# COMPUTE_CLUSTER0_CTL_CFG_PHY register map
Vendor: Texas Instruments
Registers are 32-bit, read-write, reset 0x0 unless marked. A register's access mark holds for its fields unless they carry their own. Offsets are as the file gives them; [hi:lo] are bit positions; {n}, {i} and the like mark numbered series.

## COMPUTE_CLUSTER0_CTL_CFG_PHY (part 4 of 4)
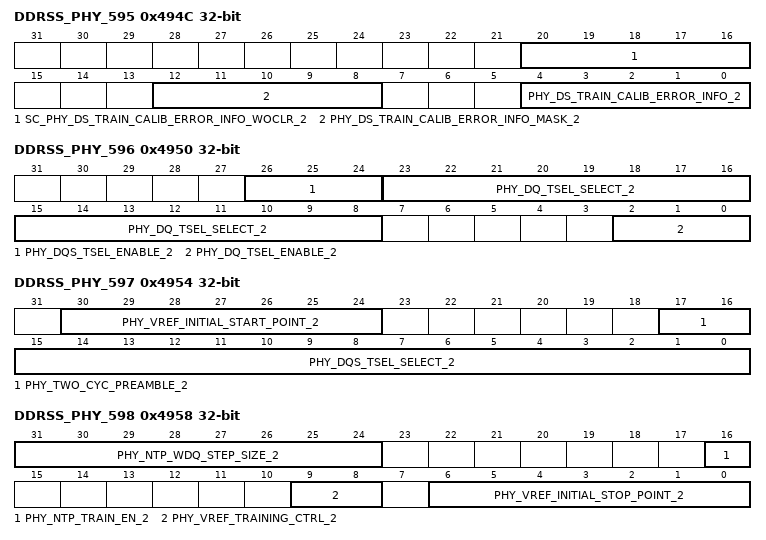
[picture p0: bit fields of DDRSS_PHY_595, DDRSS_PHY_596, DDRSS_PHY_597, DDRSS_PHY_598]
0x494C DDRSS_PHY_595 access per field
  [20:16] SC_PHY_DS_TRAIN_CALIB_ERROR_INFO_WOCLR_2 wo — Data slice level training/calibration Error Info for slice 2.
  [12:8] PHY_DS_TRAIN_CALIB_ERROR_INFO_MASK_2 rw — Data slice level training/calibration Error Info Mask for slice 2.
  [4:0] PHY_DS_TRAIN_CALIB_ERROR_INFO_2 ro — Data slice level training/calibration Error Info for slice 2.
0x4950 DDRSS_PHY_596
  [26:24] PHY_DQS_TSEL_ENABLE_2 — Operation type tsel enables for DQS signals for slice 2.
  [23:8] PHY_DQ_TSEL_SELECT_2 — Operation type tsel select values for DQ/DM signals for slice 2.
  [2:0] PHY_DQ_TSEL_ENABLE_2 — Operation type tsel enables for DQ/DM signals for slice 2.
0x4954 DDRSS_PHY_597
  [30:24] PHY_VREF_INITIAL_START_POINT_2 — Data slice initial VREF training start value for slice 2.
  [17:16] PHY_TWO_CYC_PREAMBLE_2 — 2 cycle preamble support for slice 2.
  [15:0] PHY_DQS_TSEL_SELECT_2 — Operation type tsel select values for DQS signals for slice 2.
0x4958 DDRSS_PHY_598
  [31:24] PHY_NTP_WDQ_STEP_SIZE_2 — Step size of WR DQ slave delay during No-Topology training for slice 2.
  [16] PHY_NTP_TRAIN_EN_2 — Enable for No-Topology training for slice 2.
  [9:8] PHY_VREF_TRAINING_CTRL_2 — Data slice vref training enable control for slice 2.
  [6:0] PHY_VREF_INITIAL_STOP_POINT_2 — Data slice initial VREF training stop value for slice 2.
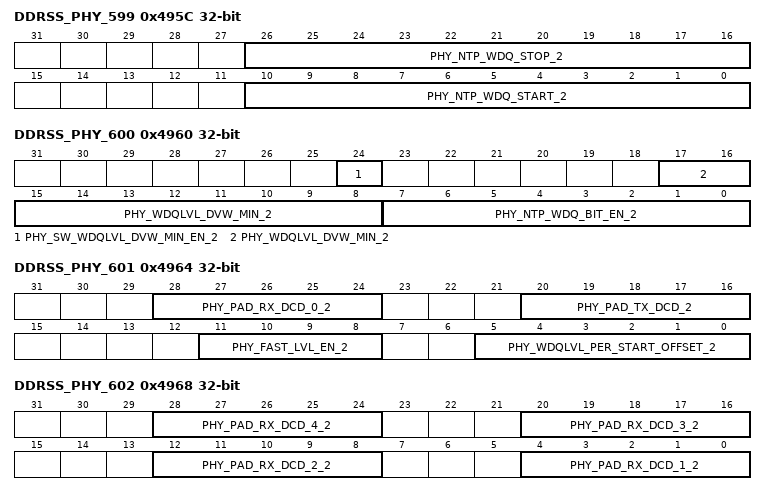
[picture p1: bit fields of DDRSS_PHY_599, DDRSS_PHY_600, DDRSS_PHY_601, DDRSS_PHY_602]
0x495C DDRSS_PHY_599
  [26:16] PHY_NTP_WDQ_STOP_2 — End of WR DQ slave delay in No-Topology training for slice 2.
  [10:0] PHY_NTP_WDQ_START_2 — Starting WR DQ slave delay in No-Topology training for slice 2.
0x4960 DDRSS_PHY_600
  [24] PHY_SW_WDQLVL_DVW_MIN_EN_2 — SW override to enable use of PHY_WDQLVL_DVW_MIN for slice 2.
  [17:8] PHY_WDQLVL_DVW_MIN_2 — Minimum data valid window across DQs and ranks for slice 2.
  [7:0] PHY_NTP_WDQ_BIT_EN_2 — Enable Bit for WR DQ during No-Topology training for slice 2.
0x4964 DDRSS_PHY_601
  [28:24] PHY_PAD_RX_DCD_0_2 — Controls RX_DCD pin for each pad for slice 2.
  [20:16] PHY_PAD_TX_DCD_2 — Controls TX_DCD pin for each pad for slice 2.
  [11:8] PHY_FAST_LVL_EN_2 — Enable for fast multi-pattern window search for slice 2.
  [5:0] PHY_WDQLVL_PER_START_OFFSET_2 — Peridic training start point offset for slice 2.
0x4968 DDRSS_PHY_602
  [8n-4:8n-8] PHY_PAD_RX_DCD_{n}_2 (n=1..4) — Controls RX_DCD pin for each pad for slice 2.
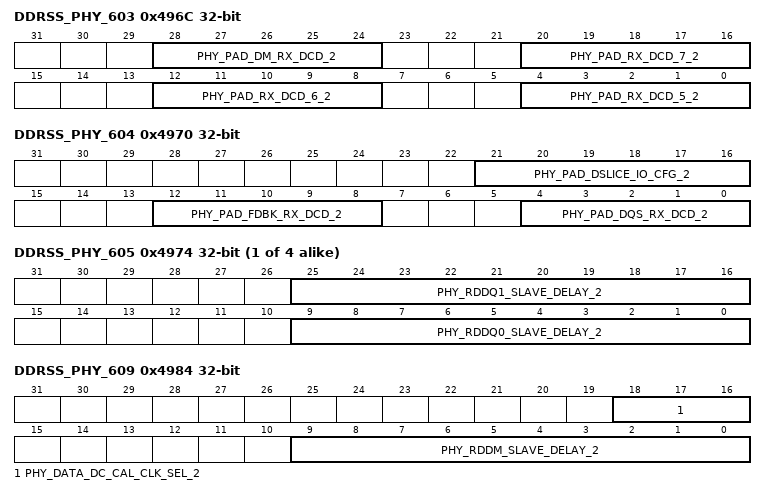
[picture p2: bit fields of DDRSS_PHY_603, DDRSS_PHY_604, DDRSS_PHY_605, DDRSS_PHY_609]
0x496C DDRSS_PHY_603
  [28:24] PHY_PAD_DM_RX_DCD_2 — Controls RX_DCD pin for dm pad for slice 2.
  [20:16] PHY_PAD_RX_DCD_7_2 — Controls RX_DCD pin for each pad for slice 2.
  [12:8] PHY_PAD_RX_DCD_6_2 — Controls RX_DCD pin for each pad for slice 2.
  [4:0] PHY_PAD_RX_DCD_5_2 — Controls RX_DCD pin for each pad for slice 2.
0x4970 DDRSS_PHY_604
  [21:16] PHY_PAD_DSLICE_IO_CFG_2 — Controls PCLK/PARK pin for pad for slice 2.
  [12:8] PHY_PAD_FDBK_RX_DCD_2 — Controls RX_DCD pin for fdbk pad for slice 2.
  [4:0] PHY_PAD_DQS_RX_DCD_2 — Controls RX_DCD pin for dqs pad for slice 2.
{0x4000+4i} DDRSS_PHY_{i} (i=605..608)
  [25:16] PHY_RDDQ{2i-1209}_SLAVE_DELAY_2 — Read DQ{2i-1209} slave delay setting for slice 2.
  [9:0] PHY_RDDQ{2i-1210}_SLAVE_DELAY_2 — Read DQ{2i-1210} slave delay setting for slice 2.
0x4984 DDRSS_PHY_609
  [18:16] PHY_DATA_DC_CAL_CLK_SEL_2 — Determines DCC CAL clock for slice 2.
  [9:0] PHY_RDDM_SLAVE_DELAY_2 — Read DM/DBI slave delay setting for slice 2.
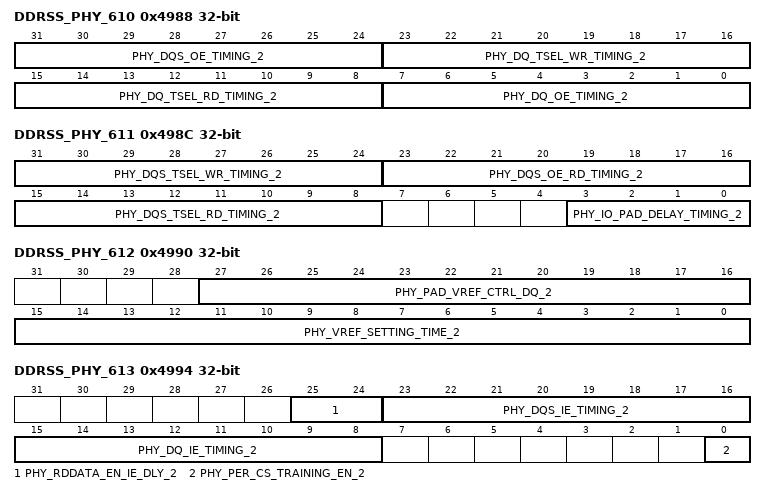
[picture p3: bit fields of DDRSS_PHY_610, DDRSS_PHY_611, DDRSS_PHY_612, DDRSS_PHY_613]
0x4988 DDRSS_PHY_610
  [31:24] PHY_DQS_OE_TIMING_2 — Start/end timing values for DQS output enable signals for slice 2.
  [23:16] PHY_DQ_TSEL_WR_TIMING_2 — Start/end timing values for DQ/DM write based termination enable and select signals for slice 2.
  [15:8] PHY_DQ_TSEL_RD_TIMING_2 — Start/end timing values for DQ/DM read based termination enable and select signals for slice 2.
  [7:0] PHY_DQ_OE_TIMING_2 — Start/end timing values for DQ/DM output enable signals for slice 2.
0x498C DDRSS_PHY_611
  [31:24] PHY_DQS_TSEL_WR_TIMING_2 — Start/end timing values for DQS write based termination enable and select signals for slice 2.
  [23:16] PHY_DQS_OE_RD_TIMING_2 — Start/end timing values for DQS read based OE extension for slice 2.
  [15:8] PHY_DQS_TSEL_RD_TIMING_2 — Start/end timing values for DQS read based termination enable and select signals for slice 2.
  [3:0] PHY_IO_PAD_DELAY_TIMING_2 — Feedback pad's OPAD and IPAD delay timing for slice 2.
0x4990 DDRSS_PHY_612
  [27:16] PHY_PAD_VREF_CTRL_DQ_2 — Pad VREF control settings for DQ slice 2.
  [15:0] PHY_VREF_SETTING_TIME_2 — Number of cycles for vref settle after setting is changed for slice 2.
0x4994 DDRSS_PHY_613
  [25:24] PHY_RDDATA_EN_IE_DLY_2 — Number of cycles that the dfi_rddata_en signal is earlier than necessary for input enable generation for slice 2.
  [23:16] PHY_DQS_IE_TIMING_2 — Start/end timing values for DQS input enable signals for slice 2.
  [15:8] PHY_DQ_IE_TIMING_2 — Start/end timing values for DQ/DM input enable signals for slice 2.
  [0] PHY_PER_CS_TRAINING_EN_2 — Enables the per-rank training and read/write timing capabilities for slice 2.
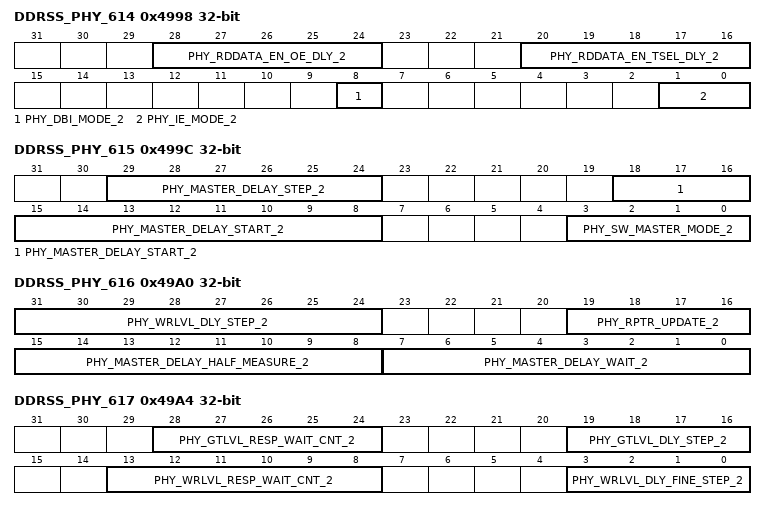
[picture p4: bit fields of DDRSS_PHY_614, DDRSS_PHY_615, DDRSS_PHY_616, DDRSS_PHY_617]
0x4998 DDRSS_PHY_614
  [28:24] PHY_RDDATA_EN_OE_DLY_2 — Number of cycles that the dfi_rddata_en signal is earlier than necessary for LP4 OE extension generation for slice 2.
  [20:16] PHY_RDDATA_EN_TSEL_DLY_2 — Number of cycles that the dfi_rddata_en signal is earlier than necessary for TSEL enable generation for slice 2.
  [8] PHY_DBI_MODE_2 — DBI mode for slice 2.
  [1:0] PHY_IE_MODE_2 — Input enable mode bits for slice 2.
0x499C DDRSS_PHY_615
  [29:24] PHY_MASTER_DELAY_STEP_2 — Incremental step size for master delay line locking algorithm for slice 2.
  [18:8] PHY_MASTER_DELAY_START_2 — Start value for master delay line locking algorithm for slice 2.
  [3:0] PHY_SW_MASTER_MODE_2 — Master delay line override settings for slice 2.
0x49A0 DDRSS_PHY_616
  [31:24] PHY_WRLVL_DLY_STEP_2 — DQS slave delay step size during write leveling for slice 2.
  [19:16] PHY_RPTR_UPDATE_2 — Offset in cycles from the dfi_rddata_en signal to release data from the entry FIFO for slice 2.
  [15:8] PHY_MASTER_DELAY_HALF_MEASURE_2 — Defines the number of delay line elements to be considered in determing whether to lock to a half clock cycle in the data slice master for slice 2.
  [7:0] PHY_MASTER_DELAY_WAIT_2 — Wait cycles for master delay line locking algorithm for slice 2.
0x49A4 DDRSS_PHY_617
  [28:24] PHY_GTLVL_RESP_WAIT_CNT_2 — Number of cycles + 4 to wait between dfi_rddata_en and the sampling of the DQS during gate training for slice 2.
  [19:16] PHY_GTLVL_DLY_STEP_2 — DQS slave delay step size during gate training for slice 2.
  [13:8] PHY_WRLVL_RESP_WAIT_CNT_2 — Number of cycles to wait between dfi_wrlvl_strobe and the sampling of the DQs during write leveling for slice 2.
  [3:0] PHY_WRLVL_DLY_FINE_STEP_2 — DQS slave delay fine step size during write leveling for slice 2.
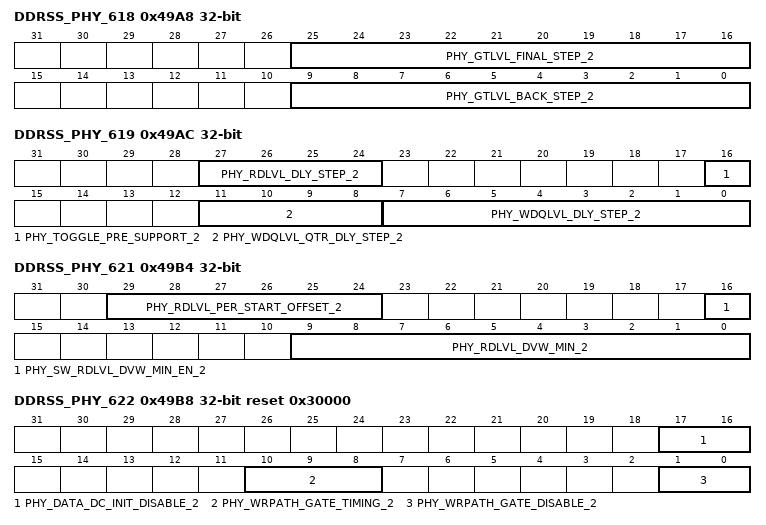
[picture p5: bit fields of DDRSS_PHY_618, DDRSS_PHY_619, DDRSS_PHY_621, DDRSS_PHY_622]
0x49A8 DDRSS_PHY_618
  [25:16] PHY_GTLVL_FINAL_STEP_2 — Final backup step delay used in gate training algorithm for slice 2.
  [9:0] PHY_GTLVL_BACK_STEP_2 — Interim backup step delay used in gate training algorithm for slice 2.
0x49AC DDRSS_PHY_619
  [27:24] PHY_RDLVL_DLY_STEP_2 — DQS slave delay step size during read leveling for slice 2.
  [16] PHY_TOGGLE_PRE_SUPPORT_2 — Support the toggle read preamble for LPDDR4 for slice 2.
  [11:8] PHY_WDQLVL_QTR_DLY_STEP_2 — Defines the step granularity for the logic to use once an edge is found for slice 2.
  [7:0] PHY_WDQLVL_DLY_STEP_2 — DQ slave delay step size during write data leveling for slice 2.
0x49B0 DDRSS_PHY_620
  [9:0] PHY_RDLVL_MAX_EDGE_2 — The maximun rdlvl slave delay search window for read eye training for slice 2.
0x49B4 DDRSS_PHY_621
  [29:24] PHY_RDLVL_PER_START_OFFSET_2 — Peridic training start point offset for slice 2.
  [16] PHY_SW_RDLVL_DVW_MIN_EN_2 — SW override to enable use of PHY_RDLVL_DVW_MIN for slice 2.
  [9:0] PHY_RDLVL_DVW_MIN_2 — Minimum data valid window across DQs and ranks for slice 2.
0x49B8 DDRSS_PHY_622 reset 0x30000
  [17:16] PHY_DATA_DC_INIT_DISABLE_2 — Disable duty cycle adjust at initialization for slice 2.
  [10:8] PHY_WRPATH_GATE_TIMING_2 — Write path clock gating timing for slice 2.
  [1:0] PHY_WRPATH_GATE_DISABLE_2 — Write path clock gating disable for slice 2.
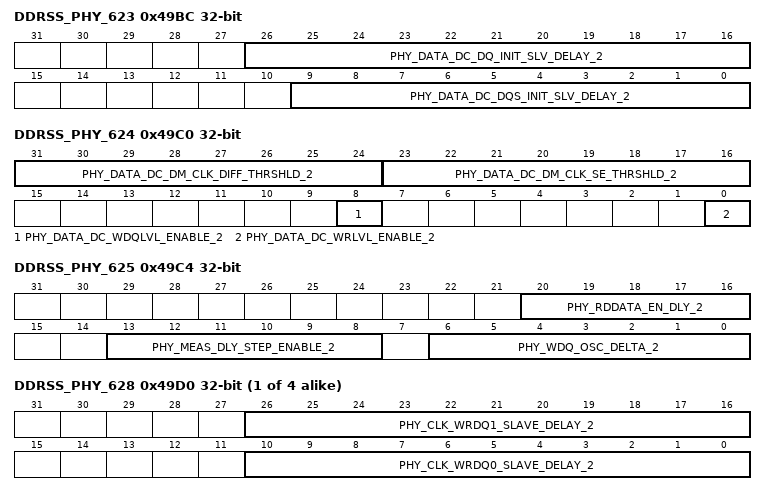
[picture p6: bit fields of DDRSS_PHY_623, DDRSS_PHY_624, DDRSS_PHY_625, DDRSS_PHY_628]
0x49BC DDRSS_PHY_623
  [26:16] PHY_DATA_DC_DQ_INIT_SLV_DELAY_2 — Initial value of write DQ slave delay for slice 2.
  [9:0] PHY_DATA_DC_DQS_INIT_SLV_DELAY_2 — Initial value of write DQS slave delay for slice 2.
0x49C0 DDRSS_PHY_624
  [31:24] PHY_DATA_DC_DM_CLK_DIFF_THRSHLD_2 — Clock measurement cell threshold offset for differential signals for slice 2.
  [23:16] PHY_DATA_DC_DM_CLK_SE_THRSHLD_2 — Clock measurement cell threshold offset for single ended signals for slice 2.
  [8] PHY_DATA_DC_WDQLVL_ENABLE_2 — Enable duty cycle adjust during write DQ training for slice 2.
  [0] PHY_DATA_DC_WRLVL_ENABLE_2 — Enable duty cycle adjust during write leveling for slice 2.
0x49C4 DDRSS_PHY_625
  [20:16] PHY_RDDATA_EN_DLY_2 — Number of cycles that the dfi_rddata_en signal is early for slice 2.
  [13:8] PHY_MEAS_DLY_STEP_ENABLE_2 — Data slice training step definition using phy_meas_dly_step_value for slice 2.
  [6:0] PHY_WDQ_OSC_DELTA_2 — Slave delay offset that applies to a 1 bit change of dfi_wdq_osc_code for slice 2.
0x49C8 DDRSS_PHY_626
  [31:0] PHY_DQ_DM_SWIZZLE0_2 — DQ/DM bit swizzling 0 for slice 2.
0x49CC DDRSS_PHY_627
  [3:0] PHY_DQ_DM_SWIZZLE1_2 — DQ/DM bit swizzling 1 for slice 2.
{0x4000+4i} DDRSS_PHY_{i} (i=628..631)
  [26:16] PHY_CLK_WRDQ{2i-1255}_SLAVE_DELAY_2 — Write clock slave delay setting for DQ{2i-1255} for slice 2.
  [10:0] PHY_CLK_WRDQ{2i-1256}_SLAVE_DELAY_2 — Write clock slave delay setting for DQ{2i-1256} for slice 2.
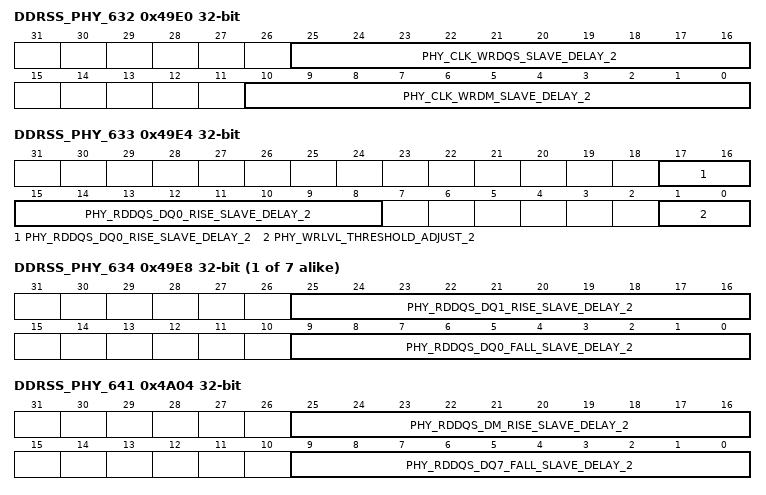
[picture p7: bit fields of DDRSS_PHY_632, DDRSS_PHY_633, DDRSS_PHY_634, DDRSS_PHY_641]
0x49E0 DDRSS_PHY_632
  [25:16] PHY_CLK_WRDQS_SLAVE_DELAY_2 — Write clock slave delay setting for DQS for slice 2.
  [10:0] PHY_CLK_WRDM_SLAVE_DELAY_2 — Write clock slave delay setting for DM for slice 2.
0x49E4 DDRSS_PHY_633
  [17:8] PHY_RDDQS_DQ0_RISE_SLAVE_DELAY_2 — Rising edge read DQS slave delay setting for DQ0 for slice 2.
  [1:0] PHY_WRLVL_THRESHOLD_ADJUST_2 — Write level threshold adjust value based on those thresholds for DQS for slice 2.
{0x4000+4i} DDRSS_PHY_{i} (i=634..640)
  [25:16] PHY_RDDQS_DQ{i-633}_RISE_SLAVE_DELAY_2 — Rising edge read DQS slave delay setting for DQ{i-633} for slice 2.
  [9:0] PHY_RDDQS_DQ{i-634}_FALL_SLAVE_DELAY_2 — Falling edge read DQS slave delay setting for DQ{i-634} for slice 2.
0x4A04 DDRSS_PHY_641
  [25:16] PHY_RDDQS_DM_RISE_SLAVE_DELAY_2 — Rising edge read DQS slave delay setting for DM for slice 2.
  [9:0] PHY_RDDQS_DQ7_FALL_SLAVE_DELAY_2 — Falling edge read DQS slave delay setting for DQ7 for slice 2.
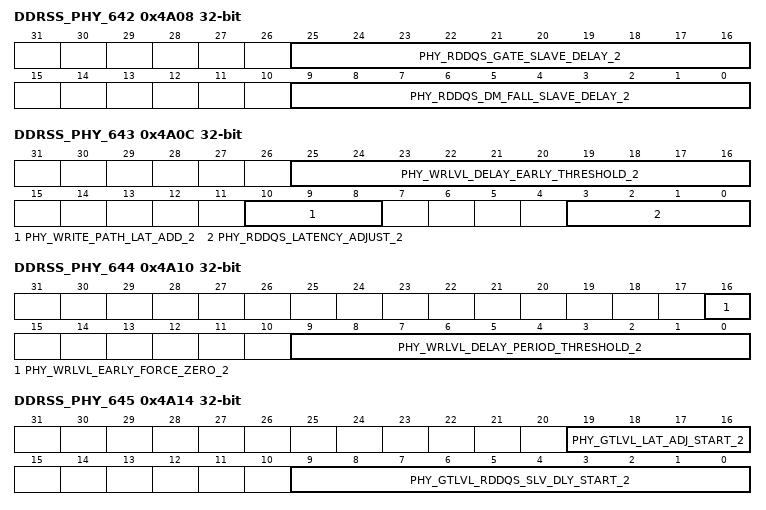
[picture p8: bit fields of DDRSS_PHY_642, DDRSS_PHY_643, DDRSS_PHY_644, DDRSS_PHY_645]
0x4A08 DDRSS_PHY_642
  [25:16] PHY_RDDQS_GATE_SLAVE_DELAY_2 — Read DQS slave delay setting for slice 2.
  [9:0] PHY_RDDQS_DM_FALL_SLAVE_DELAY_2 — Falling edge read DQS slave delay setting for DM for slice 2.
0x4A0C DDRSS_PHY_643
  [25:16] PHY_WRLVL_DELAY_EARLY_THRESHOLD_2 — Write level delay threshold above which will be considered in previous cycle for slice 2.
  [10:8] PHY_WRITE_PATH_LAT_ADD_2 — Number of cycles to delay the incoming dfi_wrdata_en/dfi_wrdata signals for slice 2.
  [3:0] PHY_RDDQS_LATENCY_ADJUST_2 — Number of cycles to delay the incoming dfi_rddata_en for read DQS gate generation for slice 2.
0x4A10 DDRSS_PHY_644
  [16] PHY_WRLVL_EARLY_FORCE_ZERO_2 — Force the final write level delay value (that meets the early threshold) to 0 for slice 2.
  [9:0] PHY_WRLVL_DELAY_PERIOD_THRESHOLD_2 — Write level delay threshold below which will add a cycle of write path latency for slice 2.
0x4A14 DDRSS_PHY_645
  [19:16] PHY_GTLVL_LAT_ADJ_START_2 — Initial read DQS gate cycle delay from dfi_rddata_en during gate training for slice 2.
  [9:0] PHY_GTLVL_RDDQS_SLV_DLY_START_2 — Initial read DQS gate slave delay setting during gate training for slice 2.
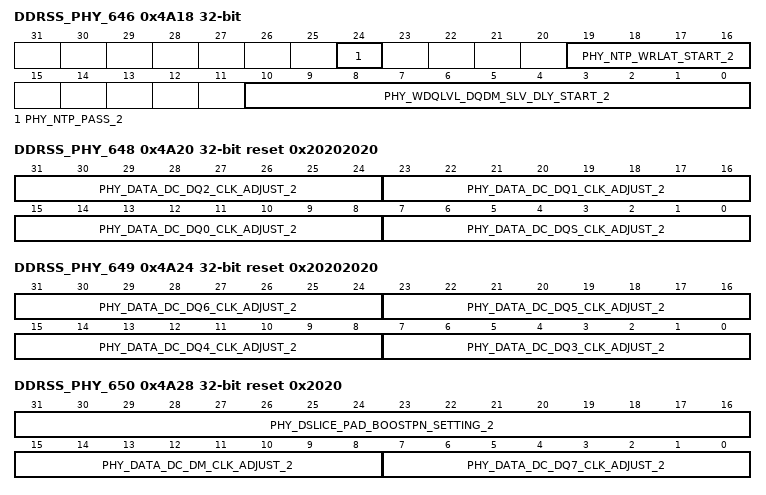
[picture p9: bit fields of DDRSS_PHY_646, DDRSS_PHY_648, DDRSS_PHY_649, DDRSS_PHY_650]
0x4A18 DDRSS_PHY_646
  [24] PHY_NTP_PASS_2 — Indicates if No-topology training found a passing result for slice 2.
  [19:16] PHY_NTP_WRLAT_START_2 — Initial value for phy_write_path_lat_add for No-topology training and early threshold for slice 2.
  [10:0] PHY_WDQLVL_DQDM_SLV_DLY_START_2 — Initial DQ/DM slave delay setting during write data leveling for slice 2.
0x4A1C DDRSS_PHY_647
  [9:0] PHY_RDLVL_RDDQS_DQ_SLV_DLY_START_2 — Read leveling starting value for the DQS/DQ slave delay settings for slice 2.
0x4A20 DDRSS_PHY_648 reset 0x20202020
  [31:24] PHY_DATA_DC_DQ2_CLK_ADJUST_2 — Adjust value of Duty Cycle Adjuster for slice 2.
  [23:16] PHY_DATA_DC_DQ1_CLK_ADJUST_2 — Adjust value of Duty Cycle Adjuster for slice 2.
  [15:8] PHY_DATA_DC_DQ0_CLK_ADJUST_2 — Adjust value of Duty Cycle Adjuster for slice 2.
  [7:0] PHY_DATA_DC_DQS_CLK_ADJUST_2 — Adjust value of Duty Cycle Adjuster for slice 2.
0x4A24 DDRSS_PHY_649 reset 0x20202020
  [8n-17:8n-24] PHY_DATA_DC_DQ{n}_CLK_ADJUST_2 (n=3..6) — Adjust value of Duty Cycle Adjuster for slice 2.
0x4A28 DDRSS_PHY_650 reset 0x2020
  [31:16] PHY_DSLICE_PAD_BOOSTPN_SETTING_2 — Setting for boost P/N of pad for slice 2.
  [15:8] PHY_DATA_DC_DM_CLK_ADJUST_2 — Adjust value of Duty Cycle Adjuster for slice 2.
  [7:0] PHY_DATA_DC_DQ7_CLK_ADJUST_2 — Adjust value of Duty Cycle Adjuster for slice 2.
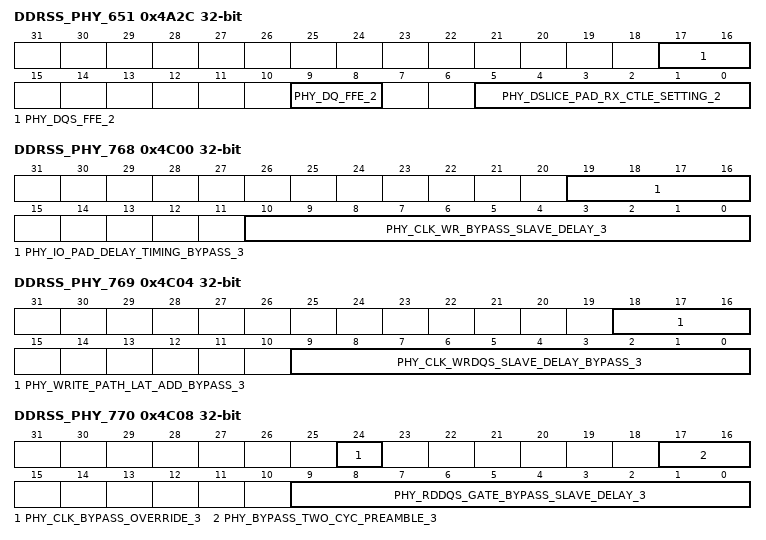
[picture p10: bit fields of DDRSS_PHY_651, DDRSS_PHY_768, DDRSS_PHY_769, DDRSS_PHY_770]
0x4A2C DDRSS_PHY_651
  [17:16] PHY_DQS_FFE_2 — TX_FFE setting for DQS pad for slice 2.
  [9:8] PHY_DQ_FFE_2 — TX_FFE setting for DQ/DM pad for slice 2.
  [5:0] PHY_DSLICE_PAD_RX_CTLE_SETTING_2 — Setting for RX ctle P/N of pad for slice 2.
0x4C00 DDRSS_PHY_768
  [19:16] PHY_IO_PAD_DELAY_TIMING_BYPASS_3 — Feedback pad's OPAD and IPAD delay timing on bypass mode for slice 3.
  [10:0] PHY_CLK_WR_BYPASS_SLAVE_DELAY_3 — Write data clock bypass mode slave delay setting for slice 3.} PADDING_BEFORE
0x4C04 DDRSS_PHY_769
  [18:16] PHY_WRITE_PATH_LAT_ADD_BYPASS_3 — Number of cycles on bypass mode to delay the incoming dfi_wrdata_en/dfi_wrdata signals for slice 3.
  [9:0] PHY_CLK_WRDQS_SLAVE_DELAY_BYPASS_3 — Write DQS bypass mode slave delay setting for slice 3.
0x4C08 DDRSS_PHY_770
  [24] PHY_CLK_BYPASS_OVERRIDE_3 — Bypass mode override setting for slice 3.
  [17:16] PHY_BYPASS_TWO_CYC_PREAMBLE_3 — Two_cycle_preamble for bypass mode for slice 3.
  [9:0] PHY_RDDQS_GATE_BYPASS_SLAVE_DELAY_3 — Read DQS bypass mode slave delay setting for slice 3.
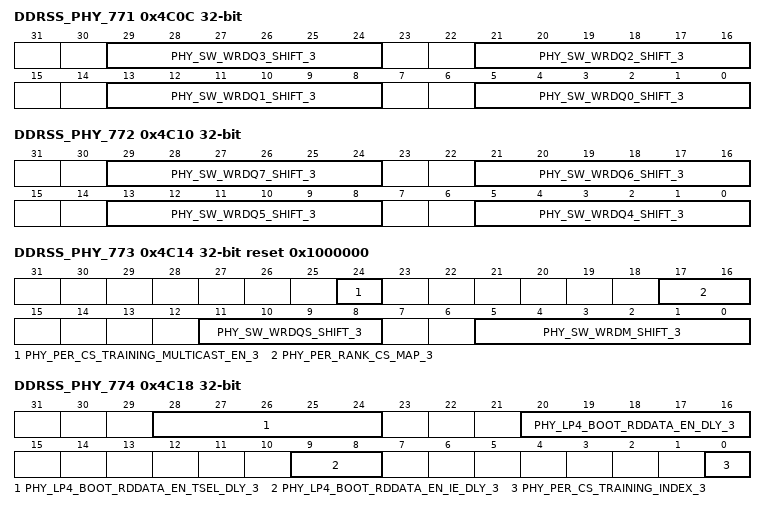
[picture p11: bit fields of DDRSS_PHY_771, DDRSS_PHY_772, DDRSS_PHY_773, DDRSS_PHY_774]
0x4C0C DDRSS_PHY_771
  [8n+5:8n] PHY_SW_WRDQ{n}_SHIFT_3 (n=0..3) — Manual override of automatic half_cycle_shift/cycle_shift for write DQ{n} for slice 3.
0x4C10 DDRSS_PHY_772
  [8n-27:8n-32] PHY_SW_WRDQ{n}_SHIFT_3 (n=4..7) — Manual override of automatic half_cycle_shift/cycle_shift for write DQ{n} for slice 3.
0x4C14 DDRSS_PHY_773 reset 0x1000000
  [24] PHY_PER_CS_TRAINING_MULTICAST_EN_3 — When set, a register write will update parameters for all ranks at the same time in slice 3.
  [17:16] PHY_PER_RANK_CS_MAP_3 — Per-rank CS map for slice 3.
  [11:8] PHY_SW_WRDQS_SHIFT_3 — Manual override of automatic half_cycle_shift/cycle_shift for write DQS for slice 3.
  [5:0] PHY_SW_WRDM_SHIFT_3 — Manual override of automatic half_cycle_shift/cycle_shift for write DM for slice 3.
0x4C18 DDRSS_PHY_774
  [28:24] PHY_LP4_BOOT_RDDATA_EN_TSEL_DLY_3 — For LPDDR4 boot frequency, the number of cycles that the dfi_rddata_en signal is earlier than necessary for TSEL enable generation for slice 3.
  [20:16] PHY_LP4_BOOT_RDDATA_EN_DLY_3 — For LPDDR4 boot frequency, the number of cycles that the dfi_rddata_en signal is early for slice 3.
  [9:8] PHY_LP4_BOOT_RDDATA_EN_IE_DLY_3 — For LPDDR4 boot frequency, the number of cycles that the dfi_rddata_en signal is earlier than necessary for input enable generation for slice 3.
  [0] PHY_PER_CS_TRAINING_INDEX_3 — For per-rank training, indicates which rank's paramters are read/written for slice 3.
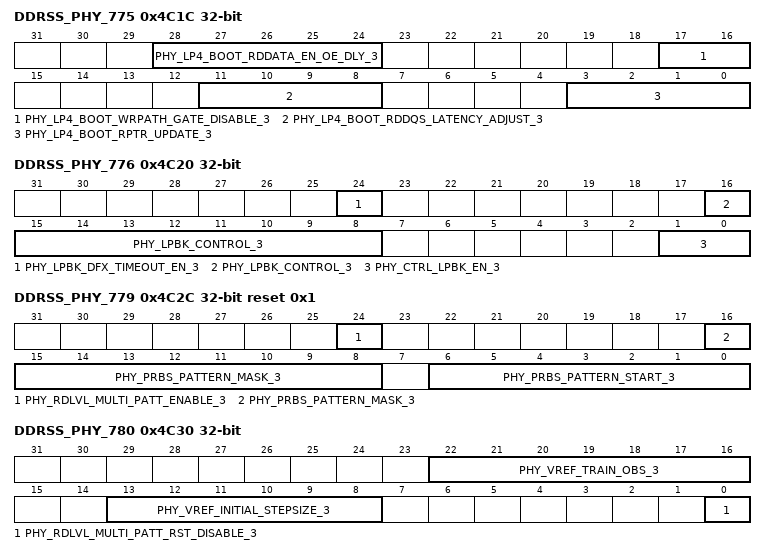
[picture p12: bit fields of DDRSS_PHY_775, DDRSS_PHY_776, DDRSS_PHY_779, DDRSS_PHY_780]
0x4C1C DDRSS_PHY_775
  [28:24] PHY_LP4_BOOT_RDDATA_EN_OE_DLY_3 — For LPDDR4 boot frequency, the number of cycles that the dfi_rddata_en signal is earlier than necessary for extended OE generation for slice 3.
  [17:16] PHY_LP4_BOOT_WRPATH_GATE_DISABLE_3 — For LPDDR4 boot frequency, write path clock gating disable for slice 3.
  [11:8] PHY_LP4_BOOT_RDDQS_LATENCY_ADJUST_3 — For LPDDR4 boot frequency, the number of cycles to delay the incoming dfi_rddata_en for read DQS gate generation for slice 3.
  [3:0] PHY_LP4_BOOT_RPTR_UPDATE_3 — For LPDDR4 boot frequency, the offset in cycles from the dfi_rddata_en signal to releasing data from the entry FIFO for slice 3.
0x4C20 DDRSS_PHY_776
  [24] PHY_LPBK_DFX_TIMEOUT_EN_3 — Loopback read only test timeout mechanism enable for slice 3.
  [16:8] PHY_LPBK_CONTROL_3 — Loopback control bits for slice 3.
  [1:0] PHY_CTRL_LPBK_EN_3 — Loopback control en for slice 3.
0x4C24 DDRSS_PHY_777
  [31:0] PHY_AUTO_TIMING_MARGIN_CONTROL_3 — Auto timing marging control bits for slice 3.
0x4C28 DDRSS_PHY_778 ro
  [27:0] PHY_AUTO_TIMING_MARGIN_OBS_3 — Observation register for the auto_timing_margin for slice 3.
0x4C2C DDRSS_PHY_779 reset 0x1
  [24] PHY_RDLVL_MULTI_PATT_ENABLE_3 — Read Leveling Multi-pattern enable for slice 3.
  [16:8] PHY_PRBS_PATTERN_MASK_3 — PRBS7 mask signal for slice 3.
  [6:0] PHY_PRBS_PATTERN_START_3 — PRBS7 start pattern for slice 3.
0x4C30 DDRSS_PHY_780 access per field
  [22:16] PHY_VREF_TRAIN_OBS_3 ro — Observation register for best vref value for slice 3.
  [13:8] PHY_VREF_INITIAL_STEPSIZE_3 rw — Data slice initial VREF training step size for slice 3.
  [0] PHY_RDLVL_MULTI_PATT_RST_DISABLE_3 rw — Read Leveling read level windows disable reset for slice 3.
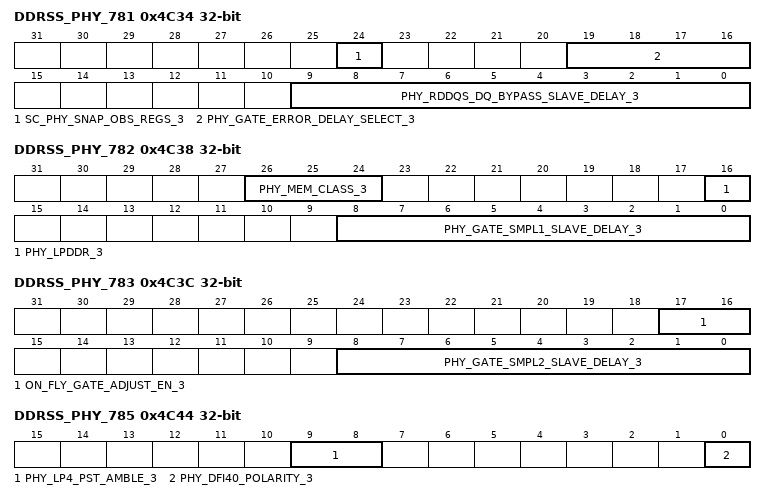
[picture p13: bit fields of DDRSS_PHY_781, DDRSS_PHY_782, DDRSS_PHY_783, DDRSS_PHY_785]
0x4C34 DDRSS_PHY_781 access per field
  [24] SC_PHY_SNAP_OBS_REGS_3 wo — Initiates a snapshot of the internal observation registers for slice 3.
  [19:16] PHY_GATE_ERROR_DELAY_SELECT_3 rw — Number of cycles to wait for the DQS gate to close before flagging an error for slice 3.
  [9:0] PHY_RDDQS_DQ_BYPASS_SLAVE_DELAY_3 rw — Read DQS data clock bypass mode slave delay setting for slice 3.
0x4C38 DDRSS_PHY_782
  [26:24] PHY_MEM_CLASS_3 — Indicates the type of DRAM for slice 3.
  [16] PHY_LPDDR_3 — Adds a cycle of delay for the slice 3 to match the address slice.
  [8:0] PHY_GATE_SMPL1_SLAVE_DELAY_3 — Number of cycles to delay the read DQS gate signal to generate gate1 signal for on-the-fly read DQS training for slice 3.
0x4C3C DDRSS_PHY_783
  [17:16] ON_FLY_GATE_ADJUST_EN_3 — Control the on-the-fly gate adjustment for slice 3.
  [8:0] PHY_GATE_SMPL2_SLAVE_DELAY_3 — Number of cycles to delay the read DQS gate signal to generate gate2 signal for on-the-fly read DQS training for slice 3.
0x4C40 DDRSS_PHY_784 ro
  [31:0] PHY_GATE_TRACKING_OBS_3 — Report the on-the-fly gate measurement result for slice 3.
0x4C44 DDRSS_PHY_785
  [9:8] PHY_LP4_PST_AMBLE_3 — Controls the read postamble extension for LPDDR4 for slice 3.
  [0] PHY_DFI40_POLARITY_3 — Indicates the dfi_wrdata_cs_n and dfi_rddata_cs_n is low active or high active for slice 3.
{0x4000+4i} DDRSS_PHY_{i} (i=786..793)
  [31:0] PHY_RDLVL_PATT{i-778}_3 — Read leveling pattern {i-778} data for slice 3.
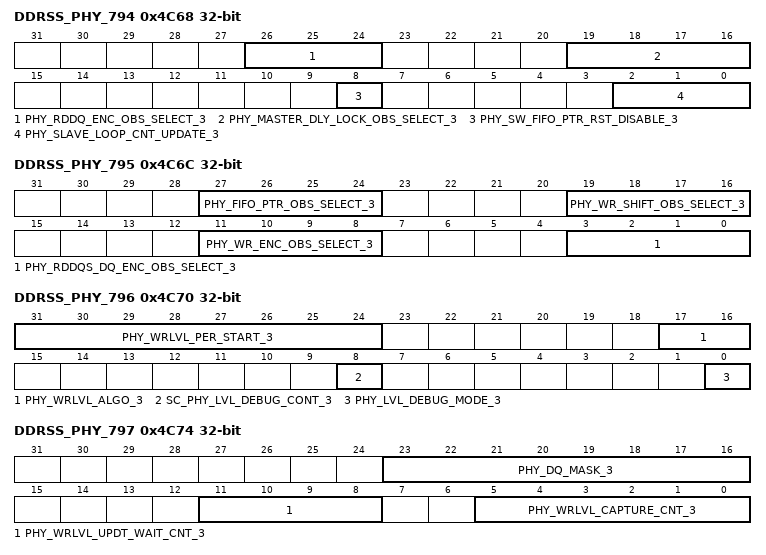
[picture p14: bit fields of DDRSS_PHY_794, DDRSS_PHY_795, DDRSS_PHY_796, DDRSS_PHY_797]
0x4C68 DDRSS_PHY_794
  [26:24] PHY_RDDQ_ENC_OBS_SELECT_3 — Select value to map the internal read DQ slave delay encoded settings to the accessible read DQ encoded slave delay observation register for slice 3.
  [19:16] PHY_MASTER_DLY_LOCK_OBS_SELECT_3 — Select value to map the internal master delay observation registers to the accessible master delay observation register for slice 3.
  [8] PHY_SW_FIFO_PTR_RST_DISABLE_3 — Disables automatic reset of the read entry FIFO pointers for slice 3.
  [2:0] PHY_SLAVE_LOOP_CNT_UPDATE_3 — Reserved for future use for slice 3.
0x4C6C DDRSS_PHY_795
  [27:24] PHY_FIFO_PTR_OBS_SELECT_3 — Select value to map the internal read entry FIFO read/write pointers to the accessible read entry FIFO pointer observation register for slice 3.
  [19:16] PHY_WR_SHIFT_OBS_SELECT_3 — Select value to map the internal write DQ/DQS automatic cycle/half_cycle shift settings to the accessible write DQ/DQS shift observation register for slice 3.
  [11:8] PHY_WR_ENC_OBS_SELECT_3 — Select value to map the internal write DQ slave delay encoded settings to the accessible write DQ encoded slave delay observation register for slice 3.
  [3:0] PHY_RDDQS_DQ_ENC_OBS_SELECT_3 — Select value to map the internal read DQS DQ rise/fall slave delay encoded settings to the accessible read DQS DQ rise/fall encoded slave delay observation registers for slice 3.
0x4C70 DDRSS_PHY_796 access per field
  [31:24] PHY_WRLVL_PER_START_3 rw — Observation register for write leveling status for slice 3.
  [17:16] PHY_WRLVL_ALGO_3 rw — Write leveling algorithm selection for slice 3.
  [8] SC_PHY_LVL_DEBUG_CONT_3 wo — Allows the leveling state machine to advance (when in debug mode) for slice 3.
  [0] PHY_LVL_DEBUG_MODE_3 rw — Enables leveling debug mode for slice 3.
0x4C74 DDRSS_PHY_797
  [23:16] PHY_DQ_MASK_3 — For ECC slice, should set this register to do DQ bit mask for slice 3.
  [11:8] PHY_WRLVL_UPDT_WAIT_CNT_3 — Number of cycles to wait after changing DQS slave delay setting during write leveling for slice 3.
  [5:0] PHY_WRLVL_CAPTURE_CNT_3 — Number of samples to take at each DQS slave delay setting during write leveling for slice 3.
0x4C78 DDRSS_PHY_798
  [27:24] PHY_GTLVL_UPDT_WAIT_CNT_3 — Number of cycles + 4 to wait after changing DQS slave delay setting during gate training for slice 3.
  [21:16] PHY_GTLVL_CAPTURE_CNT_3 — Number of samples to take at each DQS slave delay setting during gate training for slice 3.
  [9:0] PHY_GTLVL_PER_START_3 — Value to be added to the current gate delay position as the staring point for periodic gate training for slice 3.
0x4C7C DDRSS_PHY_799
  [28:24] PHY_RDLVL_RDDQS_DQ_OBS_SELECT_3 — Select value to map an individual DQ data window leading/trailing edge to the leading/trailing edge observation registers during read leveling for slice 3.
  [17:16] PHY_RDLVL_OP_MODE_3 — Read leveling algorithm select for slice 3.
  [11:8] PHY_RDLVL_UPDT_WAIT_CNT_3 — Number of cycles to wait after changing DQS slave delay setting during read leveling for slice 3.
  [5:0] PHY_RDLVL_CAPTURE_CNT_3 — Number of samples to take at each DQS slave delay setting during read leveling for slice 3.
0x4C80 DDRSS_PHY_800
  [29:24] PHY_WDQLVL_BURST_CNT_3 — Defines the write/read burst length in bytes during the write data leveling sequence for slice 3.
  [23:16] PHY_WDQLVL_CLK_JITTER_TOLERANCE_3 — Defines the minimum gap requirment for the LE and TE window for slice 3.
  [15:8] PHY_RDLVL_DATA_MASK_3 — Per-bit mask for read leveling for slice 3.
  [7:0] PHY_RDLVL_PERIODIC_OBS_SELECT_3 — Select value to map an individual DQ data window leading/trailing edge to the leading/trailing edge observation registers during periodic read leveling for slice 3.
0x4C84 DDRSS_PHY_801
  [27:24] PHY_WDQLVL_UPDT_WAIT_CNT_3 — Number of cycles to wait after changing the DQ slave delay setting during write data leveling for slice 3.
  [18:8] PHY_WDQLVL_DQDM_SLV_DLY_JUMP_OFFSET_3 — Defines the write/read burst length in bytes during the write data leveling sequence for slice 3.
  [2:0] PHY_WDQLVL_PATT_3 — Defines the training patterns to be used during the write data leveling sequence for slice 3.
0x4C88 DDRSS_PHY_802 access per field
  [16] SC_PHY_WDQLVL_CLR_PREV_RESULTS_3 wo — Clears the previous result value to allow a clean slate comparison for future write DQ leveling results for slice 3.
  [15:8] PHY_WDQLVL_PERIODIC_OBS_SELECT_3 rw — Select value to map specific information during or post periodic write data leveling for slice 3.
  [3:0] PHY_WDQLVL_DQDM_OBS_SELECT_3 rw — Select value to map an individual DQ data window leading/trailing edge to the leading/trailing edge observation registers during write data leveling for slice 3.
0x4C8C DDRSS_PHY_803
  [8:0] PHY_WDQLVL_DATADM_MASK_3 — Per-bit mask for write data leveling for slice 3.
{0x4000+4i} DDRSS_PHY_{i} (i=804..807)
  [31:0] PHY_USER_PATT{i-804}_3 — User-defined pattern to be used during write data leveling for slice 3.
0x4CA0 DDRSS_PHY_808
  [16] PHY_NTP_MULT_TRAIN_3 — Control for single pass only No-Topology training for slice 3.
  [15:0] PHY_USER_PATT4_3 — User-defined pattern to be used during write data leveling for slice 3.
0x4CA4 DDRSS_PHY_809
  [25:16] PHY_NTP_PERIOD_THRESHOLD_3 — Threshold Criteria of period threshold after No-Topology training is completed for slice 3.
  [9:0] PHY_NTP_EARLY_THRESHOLD_3 — Threshold Criteria of early threshold after No-Topology training is completed for slice 3.
0x4CA8 DDRSS_PHY_810
  [25:16] PHY_NTP_PERIOD_THRESHOLD_MAX_3 — Maximum Threshold that phy_clk_wrdqs_slave_delay could cross boundary, to set period threshold/early threshold after No-Topology training is completed for slice 3.
  [9:0] PHY_NTP_PERIOD_THRESHOLD_MIN_3 — Minimum Threshold that phy_clk_wrdqs_slave_delay could cross boundary, to set period threshold/early threshold after No-Topology training is completed for slice 3.
0x4CAC DDRSS_PHY_811 access per field
  [23:16] PHY_FIFO_PTR_OBS_3 ro — Observation register containing read entry FIFO pointers for slice 3.
  [13:8] SC_PHY_MANUAL_CLEAR_3 wo — Manual reset/clear of internal logic for slice 3.
  [0] PHY_CALVL_VREF_DRIVING_SLICE_3 rw — Indicates if slice 3 is used to drive the VREF value to the device during CA training.
0x4CB0 DDRSS_PHY_812 ro reset 0x100000
  [31:0] PHY_LPBK_RESULT_OBS_3 — Observation register containing loopback status/results for slice 3.
0x4CB4 DDRSS_PHY_813 ro
  [26:16] PHY_MASTER_DLY_LOCK_OBS_3 — Observation register containing master delay results for slice 3.
  [15:0] PHY_LPBK_ERROR_COUNT_OBS_3 — Observation register containing total number of loopback error data for slice 3.
0x4CB8 DDRSS_PHY_814 ro
  [31:24] PHY_RDDQS_DQ_RISE_ADDER_SLV_DLY_ENC_OBS_3 — Observation register containing read DQS DQ rising edge adder slave delay encoded value for slice 3.
  [23:16] PHY_MEAS_DLY_STEP_VALUE_3 — Observation register containing fraction of the cycle in 1 delay element, numerator with demominator of 512, for slice 3.
  [14:8] PHY_RDDQS_BASE_SLV_DLY_ENC_OBS_3 — Observation register containing read DQS base slave delay encoded value for slice 3.
  [6:0] PHY_RDDQ_SLV_DLY_ENC_OBS_3 — Observation register containing read DQ slave delay encoded values for slice 3.
0x4CBC DDRSS_PHY_815 ro
  [30:24] PHY_WRDQS_BASE_SLV_DLY_ENC_OBS_3 — Observation register containing write DQS base slave delay encoded value for slice 3.
  [18:8] PHY_RDDQS_GATE_SLV_DLY_ENC_OBS_3 — Observation register containing read DQS gate slave delay encoded value for slice 3.
  [7:0] PHY_RDDQS_DQ_FALL_ADDER_SLV_DLY_ENC_OBS_3 — Observation register containing read DQS DQ falling edge adder slave delay encoded value for slice 3.
0x4CC0 DDRSS_PHY_816 ro
  [18:16] PHY_WR_SHIFT_OBS_3 — Observation register containing automatic half cycle and cycle shift values for slice 3.
  [15:8] PHY_WR_ADDER_SLV_DLY_ENC_OBS_3 — Observation register containing write adder slave delay encoded value for slice 3.
  [7:0] PHY_WRDQ_BASE_SLV_DLY_ENC_OBS_3 — Observation register containing write DQ base slave delay encoded value for slice 3.
0x4CC4 DDRSS_PHY_817 ro
  [25:16] PHY_WRLVL_HARD1_DELAY_OBS_3 — Observation register containing write leveling first hard 1 DQS slave delay for slice 3.
  [9:0] PHY_WRLVL_HARD0_DELAY_OBS_3 — Observation register containing write leveling last hard 0 DQS slave delay for slice 3.
0x4CC8 DDRSS_PHY_818 ro
  [16:0] PHY_WRLVL_STATUS_OBS_3 — Observation register containing write leveling status for slice 3.
0x4CCC DDRSS_PHY_819 ro
  [25:16] PHY_GATE_SMPL2_SLV_DLY_ENC_OBS_3 — Observation register containing gate sample2 slave delay encoded values for slice 3.
  [9:0] PHY_GATE_SMPL1_SLV_DLY_ENC_OBS_3 — Observation register containing gate sample1 slave delay encoded values for slice 3.
0x4CD0 DDRSS_PHY_820 ro
  [29:16] PHY_GTLVL_HARD0_DELAY_OBS_3 — Observation register containing gate training first hard 0 DQS slave delay for slice 3.
  [15:0] PHY_WRLVL_ERROR_OBS_3 — Observation register containing write leveling error status for slice 3.
0x4CD4 DDRSS_PHY_821 ro
  [13:0] PHY_GTLVL_HARD1_DELAY_OBS_3 — Observation register containing gate training last hard 1 DQS slave delay for slice 3.
0x4CD8 DDRSS_PHY_822 ro
  [17:0] PHY_GTLVL_STATUS_OBS_3 — Observation register containing gate training status for slice 3.
0x4CDC DDRSS_PHY_823 ro
  [25:16] PHY_RDLVL_RDDQS_DQ_TE_DLY_OBS_3 — Observation register containing read leveling data window trailing edge slave delay setting for slice 3.
  [9:0] PHY_RDLVL_RDDQS_DQ_LE_DLY_OBS_3 — Observation register containing read leveling data window leading edge slave delay setting for slice 3.
0x4CE0 DDRSS_PHY_824 ro
  [1:0] PHY_RDLVL_RDDQS_DQ_NUM_WINDOWS_OBS_3 — Observation register containing read leveling number of windows found for slice 3.
0x4CE4 DDRSS_PHY_825 ro
  [31:0] PHY_RDLVL_STATUS_OBS_3 — Observation register containing read leveling status for slice 3.
0x4CE8 DDRSS_PHY_826 ro
  [31:0] PHY_RDLVL_PERIODIC_OBS_3 — Observation register containing periodic read leveling status for slice 3.
0x4CEC DDRSS_PHY_827 ro reset 0x7FF0000
  [26:16] PHY_WDQLVL_DQDM_TE_DLY_OBS_3 — Observation register containing write data leveling data window trailing edge slave delay setting for slice 3.
  [10:0] PHY_WDQLVL_DQDM_LE_DLY_OBS_3 — Observation register containing write data leveling data window leading edge slave delay setting for slice 3.
0x4CF0 DDRSS_PHY_828 ro
  [31:0] PHY_WDQLVL_STATUS_OBS_3 — Observation register containing write data leveling status for slice 3.
0x4CF4 DDRSS_PHY_829 ro
  [31:0] PHY_WDQLVL_PERIODIC_OBS_3 — Observation register containing periodic write data leveling status for slice 3.
0x4CF8 DDRSS_PHY_830
  [30:0] PHY_DDL_MODE_3 — DDL mode for slice 3.
0x4CFC DDRSS_PHY_831
  [5:0] PHY_DDL_MASK_3 — DDL mask for slice 3.
0x4D00 DDRSS_PHY_832 ro
  [31:0] PHY_DDL_TEST_OBS_3 — DDL test observation for slice 3.
0x4D04 DDRSS_PHY_833 ro
  [31:0] PHY_DDL_TEST_MSTR_DLY_OBS_3 — DDL test observation delays for slice 3 master DDL.
0x4D08 DDRSS_PHY_834 access per field
  [24] PHY_RX_CAL_OVERRIDE_3 rw — Manual setting of RX Calibration enable for slice 3.
  [16] SC_PHY_RX_CAL_START_3 wo — Manual RX Calibration start for slice 3.
  [8] PHY_LP4_WDQS_OE_EXTEND_3 rw — LPDDR4 write preamble extension enable for slice 3.
  [7:0] PHY_DDL_TRACK_UPD_THRESHOLD_3 rw — Specify threshold value for PHY init update tracking for slice 3.
0x4D0C DDRSS_PHY_835
  [24:16] PHY_RX_CAL_DQ0_3 — RX Calibration codes for DQ0 for slice 3.
  [8] PHY_SLICE_RXCAL_SHUTOFF_FDBK_OE_3 — Data slice power reduction disable for slice 3.
  [7:0] PHY_RX_CAL_SAMPLE_WAIT_3 — RX Calibration state machine wait count for slice 3.
{0x4000+4i} DDRSS_PHY_{i} (i=836..838)
  [24:16] PHY_RX_CAL_DQ{2i-1670}_3 — RX Calibration codes for DQ{2i-1670} for slice 3.
  [8:0] PHY_RX_CAL_DQ{2i-1671}_3 — RX Calibration codes for DQ{2i-1671} for slice 3.
0x4D1C DDRSS_PHY_839
  [8:0] PHY_RX_CAL_DQ7_3 — RX Calibration codes for DQ7 for slice 3.
0x4D20 DDRSS_PHY_840
  [17:0] PHY_RX_CAL_DM_3 — RX Calibration codes for DM for slice 3.
0x4D24 DDRSS_PHY_841
  [24:16] PHY_RX_CAL_FDBK_3 — RX Calibration codes for FDBK for slice 3.
  [8:0] PHY_RX_CAL_DQS_3 — RX Calibration codes for DQS for slice 3.
0x4D28 DDRSS_PHY_842 ro
  [24:16] PHY_RX_CAL_LOCK_OBS_3 — RX Calibration lock results for slice 3.
  [10:0] PHY_RX_CAL_OBS_3 — RX Calibration results for slice 3.
0x4D2C DDRSS_PHY_843 reset 0x1
  [24] PHY_RX_CAL_COMP_VAL_3 — Expected C value from RX pad for slice 3.
  [22:16] PHY_RX_CAL_DIFF_ADJUST_3 — Fine adjustment for Single-Ended RX pad of RX CAL V2 for slice 3.
  [14:8] PHY_RX_CAL_SE_ADJUST_3 — Fine adjustment for Single-Ended RX pad of RX CAL V2 for slice 3.
  [0] PHY_RX_CAL_DISABLE_3 — RX CAL disable signal for slice 3, set 1 to bypass the rx calibration
0x4D30 DDRSS_PHY_844
  [26:16] PHY_PAD_RX_BIAS_EN_3 — Controls RX_BIAS_EN pin for each pad for slice 3.
  [11:0] PHY_RX_CAL_INDEX_MASK_3 — RX offset calibration mask of all RX pad for slice 3.
0x4D34 DDRSS_PHY_845
  [25:24] PHY_DATA_DC_WEIGHT_3 — Determines weight of average calculating for slice 3.
  [23:16] PHY_DATA_DC_CAL_TIMEOUT_3 — Determines timeout number of iteration for slice 3.
  [15:8] PHY_DATA_DC_CAL_SAMPLE_WAIT_3 — Determines number of cycles to wait for each sample for slice 3.
  [4:0] PHY_STATIC_TOG_DISABLE_3 — Control to disable toggle during static activity for slice 3.
0x4D38 DDRSS_PHY_846
  [24] PHY_DATA_DC_ADJUST_DIRECT_3 — Adjust direction for slice 3.
  [23:16] PHY_DATA_DC_ADJUST_THRSHLD_3 — Duty cycle adjust threshold around the mid-point for slice 3.
  [15:8] PHY_DATA_DC_ADJUST_SAMPLE_CNT_3 — Duty cycle adjust sample count for slice 3.
  [5:0] PHY_DATA_DC_ADJUST_START_3 — Duty cycle adjust starting value for slice 3.
0x4D3C DDRSS_PHY_847 reset 0x10000
  [26:24] PHY_FDBK_PWR_CTRL_3 — Shutoff gate feedback IO to reduce power for slice 3.
  [17:16] PHY_DATA_DC_SW_RANK_3 — Rank selection for software based duty cycle correction for slice 3.
  [8] PHY_DATA_DC_CAL_START_3 — Manual trigger for DCC for slice 3.
  [0] PHY_DATA_DC_CAL_POLARITY_3 — Calibration polarity for slice 3.
0x4D40 DDRSS_PHY_848
  [24] PHY_SLICE_PWR_RDC_DISABLE_3 — Data slice power reduction disable for slice 3.
  [16] PHY_DCC_RXCAL_CTRL_GATE_DISABLE_3 — Data slice DCC and RX_CAL block power reduction disable for slice 3.
  [8] PHY_RDPATH_GATE_DISABLE_3 — Data slice read path power reduction disable for slice 3.
  [0] PHY_SLV_DLY_CTRL_GATE_DISABLE_3 — Data slice slv_dly_control block power reduction disable for slice 3.
0x4D44 DDRSS_PHY_849 access per field
  [29:16] PHY_DS_FSM_ERROR_INFO_3 ro — Data slice level FSM Error Info for slice 3.
  [10:0] PHY_PARITY_ERROR_REGIF_3 rw — Inject parity error to register interface signals for slice 3.
0x4D48 DDRSS_PHY_850 access per field
  [29:16] SC_PHY_DS_FSM_ERROR_INFO_WOCLR_3 wo — Data slice level FSM Error Info for slice 3.
  [13:0] PHY_DS_FSM_ERROR_INFO_MASK_3 rw — Data slice level FSM Error Info Mask for slice 3.
0x4D4C DDRSS_PHY_851 access per field
  [20:16] SC_PHY_DS_TRAIN_CALIB_ERROR_INFO_WOCLR_3 wo — Data slice level training/calibration Error Info for slice 3.
  [12:8] PHY_DS_TRAIN_CALIB_ERROR_INFO_MASK_3 rw — Data slice level training/calibration Error Info Mask for slice 3.
  [4:0] PHY_DS_TRAIN_CALIB_ERROR_INFO_3 ro — Data slice level training/calibration Error Info for slice 3.
0x4D50 DDRSS_PHY_852
  [26:24] PHY_DQS_TSEL_ENABLE_3 — Operation type tsel enables for DQS signals for slice 3.
  [23:8] PHY_DQ_TSEL_SELECT_3 — Operation type tsel select values for DQ/DM signals for slice 3.
  [2:0] PHY_DQ_TSEL_ENABLE_3 — Operation type tsel enables for DQ/DM signals for slice 3.
0x4D54 DDRSS_PHY_853
  [30:24] PHY_VREF_INITIAL_START_POINT_3 — Data slice initial VREF training start value for slice 3.
  [17:16] PHY_TWO_CYC_PREAMBLE_3 — 2 cycle preamble support for slice 3.
  [15:0] PHY_DQS_TSEL_SELECT_3 — Operation type tsel select values for DQS signals for slice 3.
0x4D58 DDRSS_PHY_854
  [31:24] PHY_NTP_WDQ_STEP_SIZE_3 — Step size of WR DQ slave delay during No-Topology training for slice 3.
  [16] PHY_NTP_TRAIN_EN_3 — Enable for No-Topology training for slice 3.
  [9:8] PHY_VREF_TRAINING_CTRL_3 — Data slice vref training enable control for slice 3.
  [6:0] PHY_VREF_INITIAL_STOP_POINT_3 — Data slice initial VREF training stop value for slice 3.
0x4D5C DDRSS_PHY_855
  [26:16] PHY_NTP_WDQ_STOP_3 — End of WR DQ slave delay in No-Topology training for slice 3.
  [10:0] PHY_NTP_WDQ_START_3 — Starting WR DQ slave delay in No-Topology training for slice 3.
0x4D60 DDRSS_PHY_856
  [24] PHY_SW_WDQLVL_DVW_MIN_EN_3 — SW override to enable use of PHY_WDQLVL_DVW_MIN for slice 3.
  [17:8] PHY_WDQLVL_DVW_MIN_3 — Minimum data valid window across DQs and ranks for slice 3.
  [7:0] PHY_NTP_WDQ_BIT_EN_3 — Enable Bit for WR DQ during No-Topology training for slice 3.
0x4D64 DDRSS_PHY_857
  [28:24] PHY_PAD_RX_DCD_0_3 — Controls RX_DCD pin for each pad for slice 3.
  [20:16] PHY_PAD_TX_DCD_3 — Controls TX_DCD pin for each pad for slice 3.
  [11:8] PHY_FAST_LVL_EN_3 — Enable for fast multi-pattern window search for slice 3.
  [5:0] PHY_WDQLVL_PER_START_OFFSET_3 — Peridic training start point offset for slice 3.
0x4D68 DDRSS_PHY_858
  [8n-4:8n-8] PHY_PAD_RX_DCD_{n}_3 (n=1..4) — Controls RX_DCD pin for each pad for slice 3.
0x4D6C DDRSS_PHY_859
  [28:24] PHY_PAD_DM_RX_DCD_3 — Controls RX_DCD pin for dm pad for slice 3.
  [20:16] PHY_PAD_RX_DCD_7_3 — Controls RX_DCD pin for each pad for slice 3.
  [12:8] PHY_PAD_RX_DCD_6_3 — Controls RX_DCD pin for each pad for slice 3.
  [4:0] PHY_PAD_RX_DCD_5_3 — Controls RX_DCD pin for each pad for slice 3.
0x4D70 DDRSS_PHY_860
  [21:16] PHY_PAD_DSLICE_IO_CFG_3 — Controls PCLK/PARK pin for pad for slice 3.
  [12:8] PHY_PAD_FDBK_RX_DCD_3 — Controls RX_DCD pin for fdbk pad for slice 3.
  [4:0] PHY_PAD_DQS_RX_DCD_3 — Controls RX_DCD pin for dqs pad for slice 3.
{0x4000+4i} DDRSS_PHY_{i} (i=861..864)
  [25:16] PHY_RDDQ{2i-1721}_SLAVE_DELAY_3 — Read DQ{2i-1721} slave delay setting for slice 3.
  [9:0] PHY_RDDQ{2i-1722}_SLAVE_DELAY_3 — Read DQ{2i-1722} slave delay setting for slice 3.
0x4D84 DDRSS_PHY_865
  [18:16] PHY_DATA_DC_CAL_CLK_SEL_3 — Determines DCC CAL clock for slice 3.
  [9:0] PHY_RDDM_SLAVE_DELAY_3 — Read DM/DBI slave delay setting for slice 3.
0x4D88 DDRSS_PHY_866
  [31:24] PHY_DQS_OE_TIMING_3 — Start/end timing values for DQS output enable signals for slice 3.
  [23:16] PHY_DQ_TSEL_WR_TIMING_3 — Start/end timing values for DQ/DM write based termination enable and select signals for slice 3.
  [15:8] PHY_DQ_TSEL_RD_TIMING_3 — Start/end timing values for DQ/DM read based termination enable and select signals for slice 3.
  [7:0] PHY_DQ_OE_TIMING_3 — Start/end timing values for DQ/DM output enable signals for slice 3.
0x4D8C DDRSS_PHY_867
  [31:24] PHY_DQS_TSEL_WR_TIMING_3 — Start/end timing values for DQS write based termination enable and select signals for slice 3.
  [23:16] PHY_DQS_OE_RD_TIMING_3 — Start/end timing values for DQS read based OE extension for slice 3.
  [15:8] PHY_DQS_TSEL_RD_TIMING_3 — Start/end timing values for DQS read based termination enable and select signals for slice 3.
  [3:0] PHY_IO_PAD_DELAY_TIMING_3 — Feedback pad's OPAD and IPAD delay timing for slice 3.
0x4D90 DDRSS_PHY_868
  [27:16] PHY_PAD_VREF_CTRL_DQ_3 — Pad VREF control settings for DQ slice 3.
  [15:0] PHY_VREF_SETTING_TIME_3 — Number of cycles for vref settle after setting is changed for slice 3.
0x4D94 DDRSS_PHY_869
  [25:24] PHY_RDDATA_EN_IE_DLY_3 — Number of cycles that the dfi_rddata_en signal is earlier than necessary for input enable generation for slice 3.
  [23:16] PHY_DQS_IE_TIMING_3 — Start/end timing values for DQS input enable signals for slice 3.
  [15:8] PHY_DQ_IE_TIMING_3 — Start/end timing values for DQ/DM input enable signals for slice 3.
  [0] PHY_PER_CS_TRAINING_EN_3 — Enables the per-rank training and read/write timing capabilities for slice 3.
0x4D98 DDRSS_PHY_870
  [28:24] PHY_RDDATA_EN_OE_DLY_3 — Number of cycles that the dfi_rddata_en signal is earlier than necessary for LP4 OE extension generation for slice 3.
  [20:16] PHY_RDDATA_EN_TSEL_DLY_3 — Number of cycles that the dfi_rddata_en signal is earlier than necessary for TSEL enable generation for slice 3.
  [8] PHY_DBI_MODE_3 — DBI mode for slice 3.
  [1:0] PHY_IE_MODE_3 — Input enable mode bits for slice 3.
0x4D9C DDRSS_PHY_871
  [29:24] PHY_MASTER_DELAY_STEP_3 — Incremental step size for master delay line locking algorithm for slice 3.
  [18:8] PHY_MASTER_DELAY_START_3 — Start value for master delay line locking algorithm for slice 3.
  [3:0] PHY_SW_MASTER_MODE_3 — Master delay line override settings for slice 3.
0x4DA0 DDRSS_PHY_872
  [31:24] PHY_WRLVL_DLY_STEP_3 — DQS slave delay step size during write leveling for slice 3.
  [19:16] PHY_RPTR_UPDATE_3 — Offset in cycles from the dfi_rddata_en signal to release data from the entry FIFO for slice 3.
  [15:8] PHY_MASTER_DELAY_HALF_MEASURE_3 — Defines the number of delay line elements to be considered in determing whether to lock to a half clock cycle in the data slice master for slice 3.
  [7:0] PHY_MASTER_DELAY_WAIT_3 — Wait cycles for master delay line locking algorithm for slice 3.
0x4DA4 DDRSS_PHY_873
  [28:24] PHY_GTLVL_RESP_WAIT_CNT_3 — Number of cycles + 4 to wait between dfi_rddata_en and the sampling of the DQS during gate training for slice 3.
  [19:16] PHY_GTLVL_DLY_STEP_3 — DQS slave delay step size during gate training for slice 3.
  [13:8] PHY_WRLVL_RESP_WAIT_CNT_3 — Number of cycles to wait between dfi_wrlvl_strobe and the sampling of the DQs during write leveling for slice 3.
  [3:0] PHY_WRLVL_DLY_FINE_STEP_3 — DQS slave delay fine step size during write leveling for slice 3.
0x4DA8 DDRSS_PHY_874
  [25:16] PHY_GTLVL_FINAL_STEP_3 — Final backup step delay used in gate training algorithm for slice 3.
  [9:0] PHY_GTLVL_BACK_STEP_3 — Interim backup step delay used in gate training algorithm for slice 3.
0x4DAC DDRSS_PHY_875
  [27:24] PHY_RDLVL_DLY_STEP_3 — DQS slave delay step size during read leveling for slice 3.
  [16] PHY_TOGGLE_PRE_SUPPORT_3 — Support the toggle read preamble for LPDDR4 for slice 3.
  [11:8] PHY_WDQLVL_QTR_DLY_STEP_3 — Defines the step granularity for the logic to use once an edge is found for slice 3.
  [7:0] PHY_WDQLVL_DLY_STEP_3 — DQ slave delay step size during write data leveling for slice 3.
0x4DB0 DDRSS_PHY_876
  [9:0] PHY_RDLVL_MAX_EDGE_3 — The maximun rdlvl slave delay search window for read eye training for slice 3.
0x4DB4 DDRSS_PHY_877
  [29:24] PHY_RDLVL_PER_START_OFFSET_3 — Peridic training start point offset for slice 3.
  [16] PHY_SW_RDLVL_DVW_MIN_EN_3 — SW override to enable use of PHY_RDLVL_DVW_MIN for slice 3.
  [9:0] PHY_RDLVL_DVW_MIN_3 — Minimum data valid window across DQs and ranks for slice 3.
0x4DB8 DDRSS_PHY_878 reset 0x30000
  [17:16] PHY_DATA_DC_INIT_DISABLE_3 — Disable duty cycle adjust at initialization for slice 3.
  [10:8] PHY_WRPATH_GATE_TIMING_3 — Write path clock gating timing for slice 3.
  [1:0] PHY_WRPATH_GATE_DISABLE_3 — Write path clock gating disable for slice 3.
0x4DBC DDRSS_PHY_879
  [26:16] PHY_DATA_DC_DQ_INIT_SLV_DELAY_3 — Initial value of write DQ slave delay for slice 3.
  [9:0] PHY_DATA_DC_DQS_INIT_SLV_DELAY_3 — Initial value of write DQS slave delay for slice 3.
0x4DC0 DDRSS_PHY_880
  [31:24] PHY_DATA_DC_DM_CLK_DIFF_THRSHLD_3 — Clock measurement cell threshold offset for differential signals for slice 3.
  [23:16] PHY_DATA_DC_DM_CLK_SE_THRSHLD_3 — Clock measurement cell threshold offset for single ended signals for slice 3.
  [8] PHY_DATA_DC_WDQLVL_ENABLE_3 — Enable duty cycle adjust during write DQ training for slice 3.
  [0] PHY_DATA_DC_WRLVL_ENABLE_3 — Enable duty cycle adjust during write leveling for slice 3.
0x4DC4 DDRSS_PHY_881
  [20:16] PHY_RDDATA_EN_DLY_3 — Number of cycles that the dfi_rddata_en signal is early for slice 3.
  [13:8] PHY_MEAS_DLY_STEP_ENABLE_3 — Data slice training step definition using phy_meas_dly_step_value for slice 3.
  [6:0] PHY_WDQ_OSC_DELTA_3 — Slave delay offset that applies to a 1 bit change of dfi_wdq_osc_code for slice 3.
0x4DC8 DDRSS_PHY_882
  [31:0] PHY_DQ_DM_SWIZZLE0_3 — DQ/DM bit swizzling 0 for slice 3.
0x4DCC DDRSS_PHY_883
  [3:0] PHY_DQ_DM_SWIZZLE1_3 — DQ/DM bit swizzling 1 for slice 3.
{0x4000+4i} DDRSS_PHY_{i} (i=884..887)
  [26:16] PHY_CLK_WRDQ{2i-1767}_SLAVE_DELAY_3 — Write clock slave delay setting for DQ{2i-1767} for slice 3.
  [10:0] PHY_CLK_WRDQ{2i-1768}_SLAVE_DELAY_3 — Write clock slave delay setting for DQ{2i-1768} for slice 3.
0x4DE0 DDRSS_PHY_888
  [25:16] PHY_CLK_WRDQS_SLAVE_DELAY_3 — Write clock slave delay setting for DQS for slice 3.
  [10:0] PHY_CLK_WRDM_SLAVE_DELAY_3 — Write clock slave delay setting for DM for slice 3.
0x4DE4 DDRSS_PHY_889
  [17:8] PHY_RDDQS_DQ0_RISE_SLAVE_DELAY_3 — Rising edge read DQS slave delay setting for DQ0 for slice 3.
  [1:0] PHY_WRLVL_THRESHOLD_ADJUST_3 — Write level threshold adjust value based on those thresholds for DQS for slice 3.
{0x4000+4i} DDRSS_PHY_{i} (i=890..896)
  [25:16] PHY_RDDQS_DQ{i-889}_RISE_SLAVE_DELAY_3 — Rising edge read DQS slave delay setting for DQ{i-889} for slice 3.
  [9:0] PHY_RDDQS_DQ{i-890}_FALL_SLAVE_DELAY_3 — Falling edge read DQS slave delay setting for DQ{i-890} for slice 3.
